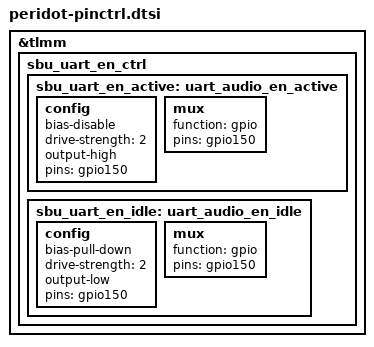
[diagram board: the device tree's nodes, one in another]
&tlmm {
	sbu_uart_en_ctrl {
		sbu_uart_en_active: uart_audio_en_active {
			config {
				bias-disable;
				drive-strength = <2>; /* 2 MA */
				output-high;
				pins = "gpio150";
			};
			mux {
				function = "gpio";
				pins = "gpio150";
			};
		};
		sbu_uart_en_idle: uart_audio_en_idle {
			config {
				bias-pull-down;
				drive-strength = <2>; /* 2 MA */
				output-low;
				pins = "gpio150";
			};
			mux {
				function = "gpio";
				pins = "gpio150";
			};
        };
    };
};
